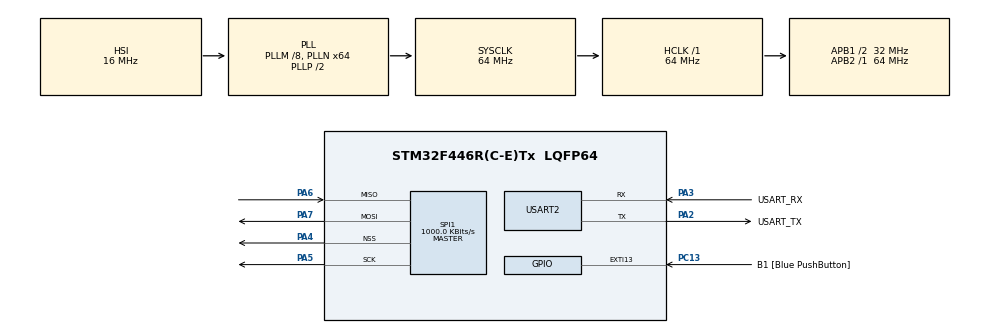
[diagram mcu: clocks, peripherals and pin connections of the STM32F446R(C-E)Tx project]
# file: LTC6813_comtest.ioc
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Mcu.Family=STM32F4
Mcu.Name=STM32F446R(C-E)Tx
Mcu.Package=LQFP64
NVIC.PriorityGroup=NVIC_PRIORITYGROUP_0
NVIC.USART2_IRQn=true\:0\:0\:false\:false\:true\:true\:true
PA13.GPIO_Label=TMS
PA13.Signal=SYS_JTMS-SWDIO
PA14.GPIO_Label=TCK
PA14.Signal=SYS_JTCK-SWCLK
PA2.GPIO_Label=USART_TX
PA2.Mode=Asynchronous
PA2.Signal=USART2_TX
PA3.GPIO_Label=USART_RX
PA3.Mode=Asynchronous
PA3.Signal=USART2_RX
PA4.Mode=NSS_Signal_Hard_Output
PA4.Signal=SPI1_NSS
PA5.Mode=Full_Duplex_Master
PA5.Signal=SPI1_SCK
PA6.Mode=Full_Duplex_Master
PA6.Signal=SPI1_MISO
PA7.Mode=Full_Duplex_Master
PA7.Signal=SPI1_MOSI
PC13.GPIO_Label=B1 [Blue PushButton]
PC13.GPIO_ModeDefaultEXTI=GPIO_MODE_IT_FALLING
PC13.Signal=GPXTI13
PC14-OSC32_IN.Signal=RCC_OSC32_IN
PC15-OSC32_OUT.Signal=RCC_OSC32_OUT
PH0-OSC_IN.Signal=RCC_OSC_IN
PH1-OSC_OUT.Signal=RCC_OSC_OUT
ProjectManager.HeapSize=0x200
ProjectManager.StackSize=0x400
ProjectManager.TargetToolchain=Makefile
RCC.48MHZClocksFreq_Value=32000000
RCC.AHBFreq_Value=64000000
RCC.APB1CLKDivider=RCC_HCLK_DIV2
RCC.APB1Freq_Value=32000000
RCC.APB1TimFreq_Value=64000000
RCC.APB2Freq_Value=64000000
RCC.APB2TimFreq_Value=64000000
RCC.CortexFreq_Value=64000000
RCC.FLatency-AdvancedSettings=FLASH_LATENCY_2
RCC.HCLKFreq_Value=64000000
RCC.HSE_VALUE=8000000
RCC.HSI_VALUE=16000000
RCC.LSE_VALUE=32768
RCC.PLLM=8
RCC.PLLN=64
RCC.SYSCLKFreq_VALUE=64000000
RCC.SYSCLKSource=RCC_SYSCLKSOURCE_PLLCLK
RCC.USBFreq_Value=64000000
RCC.VCOOutputFreq_Value=128000000
SPI1.BaudRatePrescaler=SPI_BAUDRATEPRESCALER_64
SPI1.CalculateBaudRate=1000.0 KBits/s
SPI1.Direction=SPI_DIRECTION_2LINES
SPI1.Mode=SPI_MODE_MASTER
SPI1.VirtualNSS=VM_NSSHARD
SPI1.VirtualType=VM_MASTER
USART2.VirtualMode=VM_ASYNC
board=NUCLEO-F446RE

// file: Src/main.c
/* USER CODE BEGIN Header */
/**
 ******************************************************************************
 * @file           : main.c
 * @brief          : Main program body
 ******************************************************************************
 * @attention
 *
 * <h2><center>&copy; Copyright (c) 2019 STMicroelectronics.
 * All rights reserved.</center></h2>
 *
 * This software component is licensed by ST under BSD 3-Clause license,
 * the "License"; You may not use this file except in compliance with the
 * License. You may obtain a copy of the License at:
 *                        opensource.org/licenses/BSD-3-Clause
 *
 ******************************************************************************
 */
/* USER CODE END Header */

#include "main.h"

/* USER CODE BEGIN Includes */
#include "cli.h"
#include "error.h"
#include "fenice_config.h"
/* USER CODE END Includes */

/* USER CODE BEGIN PD */
#define TEMPS_READ_INTERVAL 200
#define VOLTS_READ_INTERVAL 40
/* USER CODE END PD */

SPI_HandleTypeDef hspi1;

UART_HandleTypeDef huart2;

/* USER CODE BEGIN PV */
state_func_t *const state_table[BMS_NUM_STATES] = {
	do_state_idle, do_state_precharge, do_state_on, do_state_charge,
	do_state_halt};

transition_func_t *const transition_table[BMS_NUM_STATES][BMS_NUM_STATES] = {
	{NULL, to_precharge, NULL, NULL, to_halt},   // from idle
	{to_idle, NULL, to_on, to_charge, to_halt},  // from precharge
	{to_idle, NULL, NULL, NULL, to_halt},		 // from on
	{NULL, NULL, NULL, NULL, to_halt}};			 // from halt

const char *bms_state_names[BMS_NUM_STATES] = {[BMS_IDLE] = "idle",
											   [BMS_PRECHARGE] = "pre-charge",
											   [BMS_ON] = "on",
											   [BMS_CHARGE] = "charge",
											   [BMS_HALT] = "halt"};

const char *error_names[ERROR_NUM_ERRORS] = {
	[ERROR_LTC_PEC_ERROR] = "PEC",
	[ERROR_CELL_UNDER_VOLTAGE] = "under-voltage",
	[ERROR_CELL_OVER_VOLTAGE] = "over-voltage",
	[ERROR_CELL_OVER_TEMPERATURE] = "over-temperature",
	[ERROR_OVER_CURRENT] = "over-current",
	[ERROR_CAN] = "CAN",
	[ERROR_OK] = "ok"};

BMS_STATE_T state = BMS_IDLE;
state_global_data_t data;

cli_t cli;

DMA_HandleTypeDef hdma_adc1;

uint32_t timer_precharge = 0;
uint32_t timer_volts = 0;
uint32_t timer_temps = 0;
uint32_t timer_bal = 0;
/* USER CODE END PV */

void SystemClock_Config(void);
static void MX_GPIO_Init(void);
static void MX_SPI1_Init(void);
static void MX_USART2_UART_Init(void);

/* USER CODE BEGIN 0 */

void to_idle(state_global_data_t *data) {
	// bms_set_ts_off(&data->bms);
	// HAL_CAN_ConfigFilter(&hcan, &CAN_FILTER_NORMAL);
	// can_send(&hcan, CAN_ID_BMS, CAN_MSG_TS_OFF, 8);
}

BMS_STATE_T do_state_idle(state_global_data_t *data) {
	// if (data->can_rx.StdId == CAN_ID_ECU) {
	// 	if (data->can_rx.Data[0] == CAN_IN_TS_ON) {
	// 		// TS On
	// 		if (data->can_rx.Data[1] == 0x01) {
	// 			// Charge command
	// 			data->bms.precharge_bypass = true;
	// 		}
	// 		return BMS_PRECHARGE;
	// 	}
	// }

	return BMS_IDLE;
}

void to_precharge(state_global_data_t *data) {
	// Precharge
	// bms_precharge_start(&data->bms);
	// timer_precharge = HAL_GetTick();

	// HAL_CAN_ConfigFilter(&hcan, &CAN_FILTER_PRECHARGE);
	// can_send(&hcan, CAN_ID_OUT_INVERTER_L, CAN_MSG_BUS_VOLTAGE, 8);
}

BMS_STATE_T do_state_precharge(
	state_global_data_t *data) {  // Check for incoming voltage
	// if (data->can_rx.StdId == CAN_ID_IN_INVERTER_L) {
	// 	if (data->can_rx.Data[0] == CAN_IN_BUS_VOLTAGE) {
	// 		uint16_t bus_voltage = 0;

	// 		bus_voltage = data->can_rx.Data[2] << 8;
	// 		bus_voltage += data->can_rx.Data[1];
	// 		bus_voltage /= 31.99;

	// 		if (bus_voltage >= data->pack.total_voltage / 10000 * 0.95) {
	// 			bms_precharge_end(&data->bms);
	// 			return BMS_ON;
	// 		}
	// 	}
	// }

	// switch (bms_precharge_check(&(data)->bms)) {
	// 	case PRECHARGE_SUCCESS:
	// 		// Used when bypassing precharge

	// 		return BMS_CHARGE;
	// 		break;

	// 	case PRECHARGE_FAILURE:
	// 		// Precharge timed out

	// 		can_send_warning(&hcan, WARN_PRECHARGE_FAIL, 0);

	// 		return BMS_IDLE;
	// 		break;

	// 	case PRECHARGE_WAITING:
	// 		// If precharge is still running, send the bus voltage request

	// 		if (HAL_GetTick() - timer_precharge >= 20) {
	// 			timer_precharge = HAL_GetTick();

	// 			can_send(&hcan, CAN_ID_OUT_INVERTER_L, CAN_MSG_BUS_VOLTAGE, 8);
	// 		}
	// 		break;
	// }
	return BMS_PRECHARGE;
}

void to_charge(state_global_data_t *data) {
	// send ready to charge message (TBD)
}

BMS_STATE_T do_state_charge(state_global_data_t *data) {
	// if (data->can_rx.StdId == CAN_ID_ECU) {
	// 	if (data->can_rx.Data[0] == CAN_IN_TS_OFF) {
	// 		return BMS_IDLE;
	// 	}
	// }

	return BMS_CHARGE;
}

void to_on(state_global_data_t *data) {
	// bms_precharge_end(&data->bms);
	// HAL_CAN_ConfigFilter(&hcan, &CAN_FILTER_NORMAL);
	// can_send(&hcan, CAN_ID_BMS, CAN_MSG_TS_ON, 8);
}

BMS_STATE_T do_state_on(state_global_data_t *data) {
	// if (data->can_rx.StdId == CAN_ID_ECU) {
	// 	if (data->can_rx.Data[0] == CAN_IN_TS_OFF) {
	// 		return BMS_IDLE;
	// 	}
	// }

	return BMS_ON;
}

void to_halt(state_global_data_t *data) {
	// bms_set_ts_off(&data->bms);
	// bms_set_fault(&data->bms);

	// can_send_error(&hcan, data->error, data->error_index, &data->pack);
}

BMS_STATE_T do_state_halt(state_global_data_t *data) { return BMS_HALT; }

BMS_STATE_T run_state(BMS_STATE_T state, state_global_data_t *data) {
	BMS_STATE_T new_state = state_table[state](data);

	if (data->error != ERROR_OK) {
		new_state = BMS_HALT;
	}

	transition_func_t *transition = transition_table[state][new_state];

	if (transition) {
		transition(data);
	}

	return new_state;
}

void check_timers(state_global_data_t *data) {
	uint32_t tick = HAL_GetTick();

	// Read and send temperatures
	if (tick - timer_temps >= TEMPS_READ_INTERVAL) {
		timer_temps = tick;

		read_temps(data);
		ER_CHK(&data->error);

		// Delay voltage measurement to avoid interferences
		timer_volts = HAL_GetTick() - (VOLTS_READ_INTERVAL / 2);
	}

	// Read and send voltages and current
	if (tick - timer_volts >= VOLTS_READ_INTERVAL) {
		timer_volts = tick;

		read_volts(data);
		ER_CHK(&data->error);
	}

	if (data->balancing && tick - timer_bal >= BAL_CYCLE_LENGTH + 5000) {
		timer_bal = tick;
		if (!pack_balance_cells(&hspi1, &data->pack, &data->error)) {
			data->balancing = false;
			cli_print("turning balancing off\r\n", 23);
		}
	}

End:;
}

/**
 * @brief Runs all the checks mandated by the rules
 * @details It runs voltage and current measurements
 */
void read_volts(state_global_data_t *data) {
	// Voltages
	WARNING_T warning = WARN_OK;

	data->error_index =
		pack_update_voltages(&hspi1, &data->pack, &warning, &data->error);
	ER_CHK(&data->error);

	if (warning != WARN_OK) {
	}

	// Current
	pack_update_current(&data->pack.current, &data->error);
	ER_CHK(&data->error);

	// Update total values

End:;
}

void read_temps(state_global_data_t *data) {
	// Temperatures
	data->error_index =
		pack_update_temperatures(&hspi1, &data->pack, &data->error);
	ER_CHK(&data->error);

End:;
}
/* USER CODE END 0 */

int main(void) {

	/* MCU
	 * Configuration--------------------------------------------------------*/

	/* Reset of all peripherals, Initializes the Flash interface and the
	 * Systick. */
	HAL_Init();

	/* Configure the system clock */
	SystemClock_Config();

	/* Initialize all configured peripherals */
	MX_GPIO_Init();
	MX_SPI1_Init();
	MX_USART2_UART_Init();
	/* USER CODE BEGIN 2 */
	cli_init(&cli, &huart2);

	error_init(&data.can_error);
	data.error = ERROR_OK;

	// data->bms.pin_fault.gpio = BMS_FAULT_GPIO_Port;
	// data->bms.pin_ts_on.gpio = TS_ON_GPIO_Port;
	// data->bms.pin_chip_select.gpio = CS_6820_GPIO_Port;
	// data->bms.pin_precharge_end.gpio = PreChargeEnd_GPIO_Port;

	// data->bms.pin_fault.id = BMS_FAULT_Pin;
	// data->bms.pin_ts_on.id = TS_ON_Pin;
	// data->bms.pin_chip_select.id = CS_6820_Pin;
	// data->bms.pin_precharge_end.id = PreChargeEnd_Pin;

	// bms_write_pin(&(data->bms.pin_fault), GPIO_PIN_SET);
	// bms_write_pin(&(data->bms.pin_ts_on), GPIO_PIN_RESET);
	// bms_write_pin(&(data->bms.pin_chip_select), GPIO_PIN_SET);
	// bms_write_pin(&(data->bms.pin_precharge_end), GPIO_PIN_RESET);

	// can_init(&hcan);

	pack_init(&(data.pack));

	/* USER CODE END 2 */

	/* Infinite loop */
	while (1) {

		/* USER CODE BEGIN 3 */

		data.error = error_check_fatal(&data.can_error, HAL_GetTick());
		ER_CHK(&data.error);

		check_timers(&data);
		ER_CHK(&data.error);

		data.error_index = pack_check_errors(&data.pack, &data.error);
		ER_CHK(&data.error);

	End:
		cli_loop(&data, state);

		state = run_state(state, &data);
	}
	return 0;
	/* USER CODE END 3 */
}

void SystemClock_Config(void) {
	RCC_OscInitTypeDef RCC_OscInitStruct = {0};
	RCC_ClkInitTypeDef RCC_ClkInitStruct = {0};

	/** Configure the main internal regulator output voltage
	 */
	__HAL_RCC_PWR_CLK_ENABLE();
	__HAL_PWR_VOLTAGESCALING_CONFIG(PWR_REGULATOR_VOLTAGE_SCALE3);
	/** Initializes the CPU, AHB and APB busses clocks
	 */
	RCC_OscInitStruct.OscillatorType = RCC_OSCILLATORTYPE_HSI;
	RCC_OscInitStruct.HSIState = RCC_HSI_ON;
	RCC_OscInitStruct.HSICalibrationValue = RCC_HSICALIBRATION_DEFAULT;
	RCC_OscInitStruct.PLL.PLLState = RCC_PLL_ON;
	RCC_OscInitStruct.PLL.PLLSource = RCC_PLLSOURCE_HSI;
	RCC_OscInitStruct.PLL.PLLM = 8;
	RCC_OscInitStruct.PLL.PLLN = 64;
	RCC_OscInitStruct.PLL.PLLP = RCC_PLLP_DIV2;
	RCC_OscInitStruct.PLL.PLLQ = 2;
	RCC_OscInitStruct.PLL.PLLR = 2;
	if (HAL_RCC_OscConfig(&RCC_OscInitStruct) != HAL_OK) {
		Error_Handler();
	}
	/** Initializes the CPU, AHB and APB busses clocks
	 */
	RCC_ClkInitStruct.ClockType = RCC_CLOCKTYPE_HCLK | RCC_CLOCKTYPE_SYSCLK |
								  RCC_CLOCKTYPE_PCLK1 | RCC_CLOCKTYPE_PCLK2;
	RCC_ClkInitStruct.SYSCLKSource = RCC_SYSCLKSOURCE_PLLCLK;
	RCC_ClkInitStruct.AHBCLKDivider = RCC_SYSCLK_DIV1;
	RCC_ClkInitStruct.APB1CLKDivider = RCC_HCLK_DIV2;
	RCC_ClkInitStruct.APB2CLKDivider = RCC_HCLK_DIV1;

	if (HAL_RCC_ClockConfig(&RCC_ClkInitStruct, FLASH_LATENCY_2) != HAL_OK) {
		Error_Handler();
	}
}

static void MX_SPI1_Init(void) {

	/* SPI1 parameter configuration*/
	hspi1.Instance = SPI1;
	hspi1.Init.Mode = SPI_MODE_MASTER;
	hspi1.Init.Direction = SPI_DIRECTION_2LINES;
	hspi1.Init.DataSize = SPI_DATASIZE_8BIT;
	hspi1.Init.CLKPolarity = SPI_POLARITY_LOW;
	hspi1.Init.CLKPhase = SPI_PHASE_1EDGE;
	hspi1.Init.NSS = SPI_NSS_SOFT;
	hspi1.Init.BaudRatePrescaler = SPI_BAUDRATEPRESCALER_64;
	hspi1.Init.FirstBit = SPI_FIRSTBIT_MSB;
	hspi1.Init.TIMode = SPI_TIMODE_DISABLE;
	hspi1.Init.CRCCalculation = SPI_CRCCALCULATION_DISABLE;
	hspi1.Init.CRCPolynomial = 10;
	if (HAL_SPI_Init(&hspi1) != HAL_OK) {
		Error_Handler();
	}
}

static void MX_USART2_UART_Init(void) {

	huart2.Instance = USART2;
	huart2.Init.BaudRate = 115200;
	huart2.Init.WordLength = UART_WORDLENGTH_8B;
	huart2.Init.StopBits = UART_STOPBITS_1;
	huart2.Init.Parity = UART_PARITY_NONE;
	huart2.Init.Mode = UART_MODE_TX_RX;
	huart2.Init.HwFlowCtl = UART_HWCONTROL_NONE;
	huart2.Init.OverSampling = UART_OVERSAMPLING_16;
	if (HAL_UART_Init(&huart2) != HAL_OK) {
		Error_Handler();
	}
}

static void MX_GPIO_Init(void) {
	GPIO_InitTypeDef GPIO_InitStruct = {0};

	/* GPIO Ports Clock Enable */
	__HAL_RCC_GPIOC_CLK_ENABLE();
	__HAL_RCC_GPIOH_CLK_ENABLE();
	__HAL_RCC_GPIOA_CLK_ENABLE();
	__HAL_RCC_GPIOB_CLK_ENABLE();
	__HAL_RCC_GPIOD_CLK_ENABLE();

	/*Configure GPIO pin Output Level */
	HAL_GPIO_WritePin(SPI1_CS_GPIO_Port, SPI1_CS_Pin, GPIO_PIN_RESET);

	/*Configure GPIO pin : B1_Pin */
	GPIO_InitStruct.Pin = B1_Pin;
	GPIO_InitStruct.Mode = GPIO_MODE_IT_FALLING;
	GPIO_InitStruct.Pull = GPIO_NOPULL;
	HAL_GPIO_Init(B1_GPIO_Port, &GPIO_InitStruct);

	/*Configure GPIO pins : PC0 PC1 PC2 PC3
							 PC4 PC5 PC6 PC7
							 PC8 PC9 PC10 PC11
							 PC12 */
	GPIO_InitStruct.Pin = GPIO_PIN_0 | GPIO_PIN_1 | GPIO_PIN_2 | GPIO_PIN_3 |
						  GPIO_PIN_4 | GPIO_PIN_5 | GPIO_PIN_6 | GPIO_PIN_7 |
						  GPIO_PIN_8 | GPIO_PIN_9 | GPIO_PIN_10 | GPIO_PIN_11 |
						  GPIO_PIN_12;
	GPIO_InitStruct.Mode = GPIO_MODE_ANALOG;
	GPIO_InitStruct.Pull = GPIO_NOPULL;
	HAL_GPIO_Init(GPIOC, &GPIO_InitStruct);

	/*Configure GPIO pins : PA0 PA1 PA4 PA8
							 PA9 PA10 PA11 PA12
							 PA15 */
	GPIO_InitStruct.Pin = GPIO_PIN_0 | GPIO_PIN_1 | GPIO_PIN_4 | GPIO_PIN_8 |
						  GPIO_PIN_9 | GPIO_PIN_10 | GPIO_PIN_11 | GPIO_PIN_12 |
						  GPIO_PIN_15;
	GPIO_InitStruct.Mode = GPIO_MODE_ANALOG;
	GPIO_InitStruct.Pull = GPIO_NOPULL;
	HAL_GPIO_Init(GPIOA, &GPIO_InitStruct);

	/*Configure GPIO pins : PB0 PB1 PB2 PB10
							 PB12 PB13 PB14 PB15
							 PB3 PB4 PB5 PB7
							 PB8 PB9 */
	GPIO_InitStruct.Pin = GPIO_PIN_0 | GPIO_PIN_1 | GPIO_PIN_2 | GPIO_PIN_10 |
						  GPIO_PIN_12 | GPIO_PIN_13 | GPIO_PIN_14 |
						  GPIO_PIN_15 | GPIO_PIN_3 | GPIO_PIN_4 | GPIO_PIN_5 |
						  GPIO_PIN_7 | GPIO_PIN_8 | GPIO_PIN_9;
	GPIO_InitStruct.Mode = GPIO_MODE_ANALOG;
	GPIO_InitStruct.Pull = GPIO_NOPULL;
	HAL_GPIO_Init(GPIOB, &GPIO_InitStruct);

	/*Configure GPIO pin : PD2 */
	GPIO_InitStruct.Pin = GPIO_PIN_2;
	GPIO_InitStruct.Mode = GPIO_MODE_ANALOG;
	GPIO_InitStruct.Pull = GPIO_NOPULL;
	HAL_GPIO_Init(GPIOD, &GPIO_InitStruct);

	/*Configure GPIO pin : SPI1_CS_Pin */
	GPIO_InitStruct.Pin = SPI1_CS_Pin;
	GPIO_InitStruct.Mode = GPIO_MODE_OUTPUT_PP;
	GPIO_InitStruct.Pull = GPIO_NOPULL;
	GPIO_InitStruct.Speed = GPIO_SPEED_FREQ_LOW;
	HAL_GPIO_Init(SPI1_CS_GPIO_Port, &GPIO_InitStruct);
}

/* USER CODE BEGIN 4 */
/**
 * @brief  Rx Transfer completed callback
 * @note   This example shows a simple way to report end of IT Rx transfer,
 * and you can add your own implementation.
 * @retval None
 */
void UART_CharReception_Callback(void) {
	/* Read Received character. RXNE flag is cleared by reading of DR
	 * register
	 */

	cli_char_receive();
}

/**
 * @brief  Function called for achieving next TX Byte sending
 * @retval None
 */
void UART_TXEmpty_Callback(void) {
	// if (tx_buf.index == (ubSizeToSend - 1)) {
	/* Disable TXE interrupt */
	LL_USART_DisableIT_TXE(USART2);

	/* Enable TC interrupt */
	LL_USART_EnableIT_TC(USART2);
	//}

	/* Fill DR with a new char */
	// LL_USART_TransmitData8(USART2, aTxStartMessage[rx_buf.index++]);
}

/**
 * @brief  Function called at completion of last byte transmission
 * @retval None
 */
void UART_CharTransmitComplete_Callback(void) {
	// if (tx_buf.index == sizeof(aTxStartMessage)) {
	// 	tx_buf.index = 0;

	// 	/* Disable TC interrupt */
	LL_USART_DisableIT_TC(USART2);

	// 	/* Set Tx complete boolean to 1 */
	// 	tx_complete = 1;
	// }
}

/**
 * @brief  UART error callbacks
 * @note   This example shows a simple way to report transfer error, and you
 * can add your own implementation.
 * @retval None
 */
void UART_Error_Callback(void) {
	__IO uint32_t sr_reg;

	/* Disable USARTx_IRQn */
	NVIC_DisableIRQ(USART2_IRQn);

	/* Error handling example :
	  - Read USART SR register to identify flag that leads to IT raising
	  - Perform corresponding error handling treatment according to flag
	*/
	sr_reg = LL_USART_ReadReg(USART2, SR);
	if (sr_reg & LL_USART_SR_NE) {
		/* Turn LED2 off: Transfer error in reception/transmission process
		 */
		// BSP_LED_Off(LED2);
	} else {
		/* Turn LED2 off: Transfer error in reception/transmission process
		 */
		// BSP_LED_Off(LED2);
	}
}
/* USER CODE END 4 */

void Error_Handler(void) {
	/* USER CODE BEGIN Error_Handler_Debug */
	/* User can add his own implementation to report the HAL error return
	 * state
	 */

	/* USER CODE END Error_Handler_Debug */
}

#ifdef USE_FULL_ASSERT
/**
 * @brief  Reports the name of the source file and the source line number
 *         where the assert_param error has occurred.
 * @param  file: pointer to the source file name
 * @param  line: assert_param error line source number
 * @retval None
 */
void assert_failed(uint8_t *file, uint32_t line) {
	/* USER CODE BEGIN 6 */
	/* User can add his own implementation to report the file name and line
	   number, tex: printf("Wrong parameters value: file %s on line %d\r\n",
	   file, line) */
	/* USER CODE END 6 */
}
#endif /* USE_FULL_ASSERT */

/************************ (C) COPYRIGHT STMicroelectronics *****END OF FILE****/
